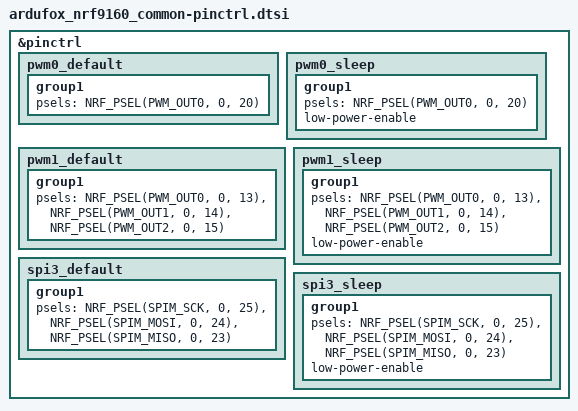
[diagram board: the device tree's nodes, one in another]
/*
 * Copyright (c) 2022 Nordic Semiconductor
 * SPDX-License-Identifier: Apache-2.0
 */

&pinctrl {
	pwm0_default: pwm0_default {
		group1 {
			psels = <NRF_PSEL(PWM_OUT0, 0, 20)>;
		};
	};

	pwm0_sleep: pwm0_sleep {
		group1 {
			psels = <NRF_PSEL(PWM_OUT0, 0, 20)>;
			low-power-enable;
		};
	};

    pwm1_default: pwm1_default {
        group1 {
            psels = <NRF_PSEL(PWM_OUT0, 0, 13)>,
                <NRF_PSEL(PWM_OUT1, 0, 14)>,
                <NRF_PSEL(PWM_OUT2, 0, 15)>;
        };
    };

    pwm1_sleep: pwm1_sleep {
        group1 {
            psels = <NRF_PSEL(PWM_OUT0, 0, 13)>,
                <NRF_PSEL(PWM_OUT1, 0, 14)>,
                <NRF_PSEL(PWM_OUT2, 0, 15)>;
            low-power-enable;
        };
    };

	
	spi3_default: spi3_default {
		group1 {
			psels = <NRF_PSEL(SPIM_SCK, 0, 25)>,
				<NRF_PSEL(SPIM_MOSI, 0, 24)>,
				<NRF_PSEL(SPIM_MISO, 0, 23)>;
		};
	};

	spi3_sleep: spi3_sleep {
		group1 {
			psels = <NRF_PSEL(SPIM_SCK, 0, 25)>,
				<NRF_PSEL(SPIM_MOSI, 0, 24)>,
				<NRF_PSEL(SPIM_MISO, 0, 23)>;
			low-power-enable;
		};
	};

};
